AUTOSAR XML (schema 00044)
package /E40_Platform_System_SystemPackage/Components
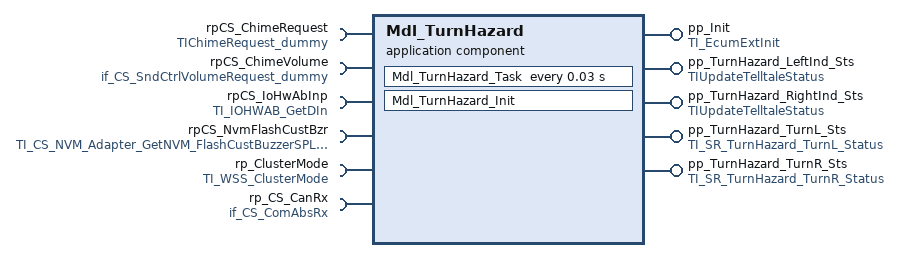
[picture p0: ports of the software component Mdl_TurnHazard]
  application sw component type Mdl_TurnHazard
    5 x provide port:
      pp_Init: server-com-spec{operation=Init, queue-length=1}, provided-interface=TI_EcumExtInit
      pp_TurnHazard_LeftInd_Sts: nonqueued-sender-com-spec{data-element=CurrentTelltaleStatus, init-value=constant-reference=Mdl_TurnHazardCurrentTelltaleStatusValue0}, provided-interface=TIUpdateTelltaleStatus
      pp_TurnHazard_RightInd_Sts: nonqueued-sender-com-spec{data-element=CurrentTelltaleStatus, init-value=constant-reference=Mdl_TurnHazardCurrentTelltaleStatusValue0}, provided-interface=TIUpdateTelltaleStatus
      pp_TurnHazard_TurnL_Sts: nonqueued-sender-com-spec{data-element=LeftIndicatorSts, init-value=constant-reference=Mdl_TurnHazardLeftIndicatorStsValue0}, provided-interface=TI_SR_TurnHazard_TurnL_Status
      pp_TurnHazard_TurnR_Sts: nonqueued-sender-com-spec{data-element=RightIndicatorSts, init-value=constant-reference=Mdl_TurnHazardRightIndicatorStsValue0}, provided-interface=TI_SR_TurnHazard_TurnR_Status
    6 x require port:
      rpCS_ChimeRequest: nonqueued-receiver-com-spec{data-element=Chime_Request, init-value=constant-reference=Mdl_TurnHazardChime_RequestValue0}, required-interface=TIChimeRequest_dummy
      rpCS_ChimeVolume: nonqueued-receiver-com-spec{data-element=UpdateChimeVolume, init-value=constant-reference=Mdl_TurnHazardUpdateChimeVolumeValue0}, required-interface=if_CS_SndCtrlVolumeRequest_dummy
      rpCS_IoHwAbInp: required-com-specs=[GetAsyncRawInput, GetInputGroup, GetProcessedInput, GetSyncRawInput], required-interface=TI_IOHWAB_GetDIn
      rpCS_NvmFlashCustBzr: nonqueued-receiver-com-spec{data-element=Nvmdata, init-value=constant-reference=Mdl_TurnHazardNvmdataValue0}, required-interface=TI_CS_NVM_Adapter_GetNVM_FlashCustBuzzerSPL_Dummy
      rp_ClusterMode: nonqueued-receiver-com-spec{data-element=WSSCurrentClusterMode, init-value=constant-reference=Mdl_TurnHazardWSSCurrentClusterModeValue0}, required-interface=TI_WSS_ClusterMode
      rp_CS_CanRx: required-interface=if_CS_ComAbsRx
        required-com-specs:
          RxCan_GetSignalValue
          RxCan_GetSignalValueU8Arr
          RxCan_SetSignalInitValue
          RxCan_SetSignalInitValueU8Arr
          RxCan_SignalClearJustRcvdStatus
          RxCan_SignalGetJustRcvdStatus
          RxCan_SignalInvalidProcessingControl
          RxCan_SignalMissingProcessingControl
          RxCan_SignalNRProcessingControl
    behavior IB_Mdl_TurnHazard
      operation invoked event OIE_pp_Init_Mdl_TurnHazard_InitTrigByInit: start-on-event=Mdl_TurnHazard_Init, operation=pp_Init.Init
      timing event TEMdl_TurnHazard_Task: start-on-event=Mdl_TurnHazard_Task, period=0.03
      port-api-options:
        enable-take-address=false, indirect-api=false, port=pp_Init
        enable-take-address=false, indirect-api=false, port=pp_TurnHazard_LeftInd_Sts
        enable-take-address=false, indirect-api=false, port=pp_TurnHazard_RightInd_Sts
        enable-take-address=false, indirect-api=false, port=pp_TurnHazard_TurnL_Sts
        enable-take-address=false, indirect-api=false, port=pp_TurnHazard_TurnR_Sts
        enable-take-address=false, indirect-api=false, port=rpCS_ChimeRequest
        enable-take-address=false, indirect-api=false, port=rpCS_ChimeVolume
        enable-take-address=false, indirect-api=false, port=rpCS_IoHwAbInp
        enable-take-address=false, indirect-api=false, port=rpCS_NvmFlashCustBzr
        enable-take-address=false, indirect-api=false, port=rp_ClusterMode
        enable-take-address=false, indirect-api=false, port=rp_CS_CanRx
      runnable Mdl_TurnHazard_Init: can-be-invoked-concurrently=true
      runnable Mdl_TurnHazard_Task: can-be-invoked-concurrently=true
        data-receive-point-by-arguments:
          4 x access:
            DRA_rpCS_ChimeRequest_Chime_Request: accessed-variable=rpCS_ChimeRequest.Chime_Request
            DRA_rpCS_ChimeVolume_UpdateChimeVolume: accessed-variable=rpCS_ChimeVolume.UpdateChimeVolume
            DRA_rpCS_NvmFlashCustBzr_Nvmdata: accessed-variable=rpCS_NvmFlashCustBzr.Nvmdata
            DRA_rp_ClusterMode_WSSCurrentClusterMode: accessed-variable=rp_ClusterMode.WSSCurrentClusterMode
        data-send-points:
          4 x access:
            DWA_pp_TurnHazard_LeftInd_Sts_CurrentTelltaleStatus: accessed-variable=pp_TurnHazard_LeftInd_Sts.CurrentTelltaleStatus
            DWA_pp_TurnHazard_RightInd_Sts_CurrentTelltaleStatus: accessed-variable=pp_TurnHazard_RightInd_Sts.CurrentTelltaleStatus
            DWA_pp_TurnHazard_TurnL_Sts_LeftIndicatorSts: accessed-variable=pp_TurnHazard_TurnL_Sts.LeftIndicatorSts
            DWA_pp_TurnHazard_TurnR_Sts_RightIndicatorSts: accessed-variable=pp_TurnHazard_TurnR_Sts.RightIndicatorSts
        13 x sync call:
          OA_rpCS_IoHwAbInp_GetAsyncRawInput: operation=rpCS_IoHwAbInp.GetAsyncRawInput
          OA_rpCS_IoHwAbInp_GetProcessedInput: operation=rpCS_IoHwAbInp.GetProcessedInput
          OA_rpCS_IoHwAbInp_GetSyncRawInput: operation=rpCS_IoHwAbInp.GetSyncRawInput
          OA_rpCS_IoHwAbInp_GetInputGroup: operation=rpCS_IoHwAbInp.GetInputGroup
          OA_rp_CS_CanRx_RxCan_GetSignalValueU8Arr: operation=rp_CS_CanRx.RxCan_GetSignalValueU8Arr
          OA_rp_CS_CanRx_RxCan_SetSignalInitValue: operation=rp_CS_CanRx.RxCan_SetSignalInitValue
          OA_rp_CS_CanRx_RxCan_SetSignalInitValueU8Arr: operation=rp_CS_CanRx.RxCan_SetSignalInitValueU8Arr
          OA_rp_CS_CanRx_RxCan_SignalInvalidProcessingControl: operation=rp_CS_CanRx.RxCan_SignalInvalidProcessingControl
          OA_rp_CS_CanRx_RxCan_SignalMissingProcessingControl: operation=rp_CS_CanRx.RxCan_SignalMissingProcessingControl
          OA_rp_CS_CanRx_RxCan_SignalNRProcessingControl: operation=rp_CS_CanRx.RxCan_SignalNRProcessingControl
          OA_rp_CS_CanRx_RxCan_SignalGetJustRcvdStatus: operation=rp_CS_CanRx.RxCan_SignalGetJustRcvdStatus
          OA_rp_CS_CanRx_RxCan_SignalClearJustRcvdStatus: operation=rp_CS_CanRx.RxCan_SignalClearJustRcvdStatus
          OA_rp_CS_CanRx_RxCan_GetSignalValue: operation=rp_CS_CanRx.RxCan_GetSignalValue
  swc implementation IMPL_Mdl_TurnHazard: behavior=IB_Mdl_TurnHazard
